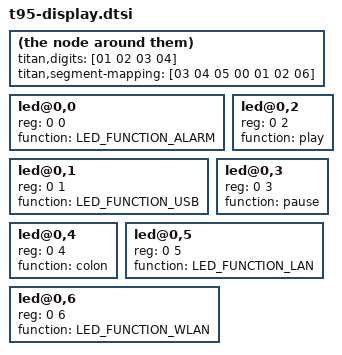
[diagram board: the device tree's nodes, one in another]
#include <dt-bindings/leds/common.h>


titan,digits = [01 02 03 04];
titan,segment-mapping = [03 04 05 00 01 02 06];
#address-cells = <2>;
#size-cells = <0>;

led@0,0 {
	reg = <0 0>;
	function = LED_FUNCTION_ALARM;
};

led@0,1 {
	reg = <0 1>;
	function = LED_FUNCTION_USB;
};

led@0,2 {
	reg = <0 2>;
	function = "play";
};

led@0,3 {
	reg = <0 3>;
	function = "pause";
};

led@0,4 {
	reg = <0 4>;
	function = "colon";
};

led@0,5 {
	reg = <0 5>;
	function = LED_FUNCTION_LAN;
};

led@0,6 {
	reg = <0 6>;
	function = LED_FUNCTION_WLAN;
};
